# S32K312_M7 register map
Vendor: NXP Semiconductors; File version: 1.3
CPU: CM7 r0p1, little endian, MPU, FPU, VTOR, 4 interrupt priority bits
Registers are 32-bit, read-write, reset 0x0 unless marked. A register's access mark holds for its fields unless they carry their own. Offsets are from the block's base; [hi:lo] are bit positions; lines under a group give offsets from that group; {n}, {i} and the like mark numbered series; 'fields as' and 'values as' point back to an identical list.

## CMU_1 — CMU_FM
Base 0x402BC020
Same registers: CMU_2 0x402BC040
0x00 GCR — Global Configuration Register
  [0] FME — Frequency Meter Enable
    0=bfv_fme_0 (Stops frequency metering); 1=bfv_fme_1 (Starts frequency metering)
0x04 RCCR — Reference Count Configuration Register
  [15:0] REF_CNT — Reference Clock Count
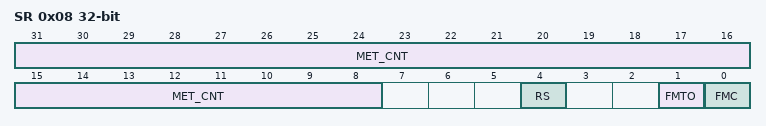
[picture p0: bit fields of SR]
0x08 SR — Status Register
  [31:8] MET_CNT ro — Meter Clock Count
  [4] RS ro — Run Status
    0=bfv_rs_0 (Frequency meter stopped); 1=bfv_rs_1 (Frequency meter running)
  [1] FMTO write-1-clears — Frequency Meter Time Out
  [0] FMC write-1-clears — Frequency Meter Operation Complete
0x0C IER — Interrupt Enable Register
  [0] FMCIE — Frequency Meter Complete Interrupt Enable
    0=bfv_fmcie_0 (Frequency Meter complete interrupt is disabled); 1=bfv_fmcie_1 (Frequency Meter complete interrupt is enabled)

## TSPC
Base 0x402C4000
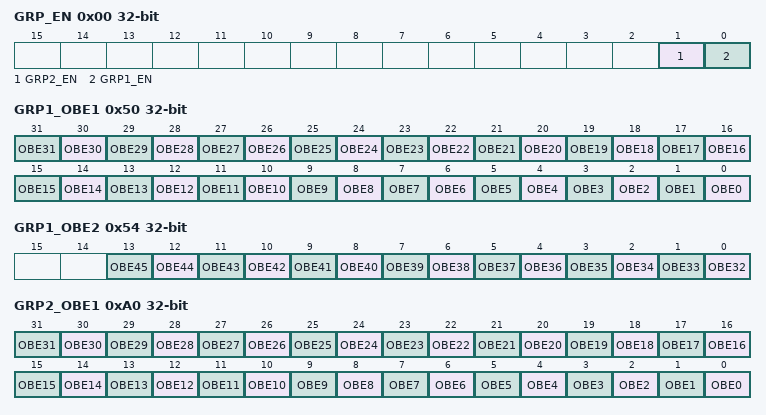
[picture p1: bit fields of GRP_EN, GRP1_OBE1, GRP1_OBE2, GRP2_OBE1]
0x00 GRP_EN — Group Enable
  [1] GRP2_EN — Enable for GRP2_OBEn Register
    0=GRP2_value0 (Disable); 1=GRP2_value1 (Enable)
  [0] GRP1_EN — Enable for GRP1_OBEn Register
    0=GRP1_value0 (Disable); 1=GRP1_value1 (Enable)
0x50 GRP1_OBE1 — Group OBE
  [n] OBE{n} (n=0..31) — Output Buffer Enable
    0=OBE{n}_value0 (OBE pad does not transition if any OBE in group transitions from high to low. The OBE pad value is unaltered at the output.); 1=OBE{n}_value1 (OBE pad transitions from high to low if any OBE in group transitions from high to low.)
0x54 GRP1_OBE2 — Group OBE
  [n-32] OBE{n} (n=32..45) — Output Buffer Enable
    values as GRP1_OBE1.OBE0
0xA0 GRP2_OBE1 — Group OBE
  fields as GRP1_OBE1
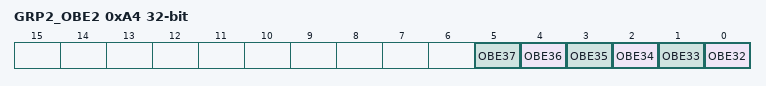
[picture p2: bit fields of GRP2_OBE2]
0xA4 GRP2_OBE2 — Group OBE
  [n-32] OBE{n} (n=32..37) — Output Buffer Enable
    values as GRP1_OBE1.OBE0

## SIRC
Base 0x402C8000
0x04 SR ro reset 0x1 — Status Register
  [0] STATUS — Status bit for SIRC
    0=bfvid_sr_status_0 (SIRC is off or unstable); 1=bfvid_sr_status_1 (SIRC is on and stable)
0x0C MISCELLANEOUS_IN — Miscellaneous input
  [8] STANDBY_ENABLE — Standby Enable for SIRC
    0=SIRC disables in Standby mode; 1=SIRC enables in Standby mode

## SXOSC
Base 0x402CC000
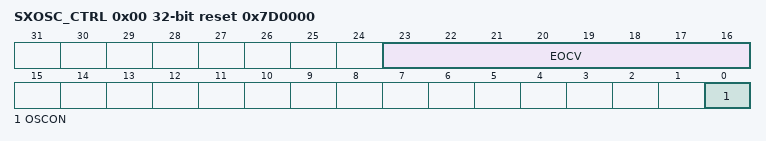
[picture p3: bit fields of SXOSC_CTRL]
0x00 SXOSC_CTRL reset 0x7D0000 — Oscillator Control
  [23:16] EOCV — End Of Count Value
  [0] OSCON — Crystal Oscillator Power-Down Control
    0=Disabled (switched off); 1=Enabled (switched on)
0x04 SXOSC_STAT ro — Oscillator Status
  [31] OSC_STAT — Crystal Oscillator Status
    0=Unstable; 1=Stable

## FIRC
Base 0x402D0000
0x04 Status_Register ro reset 0x1
  [0] STATUS — Status bit for FIRC
    0=FIRC is off or unstable; 1=FIRC is on and stable
0x08 STDBY_ENABLE — Standby Enable Register
  [0] STDBY_EN — Enables or disables FIRC in chip's Standby mode.
    0=Disabled; 1=Enabled

## FXOSC
Base 0x402D4000
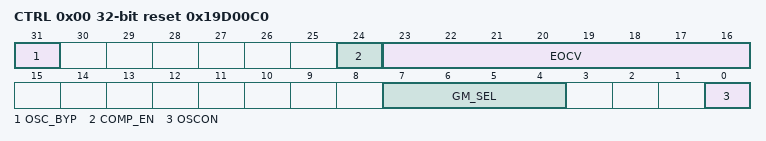
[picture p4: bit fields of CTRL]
0x00 CTRL reset 0x19D00C0 — FXOSC Control Register
  [31] OSC_BYP — Oscillator bypass
    0=Internal oscillator not bypassed; 1=Internal oscillator bypassed
  [24] COMP_EN — Comparator enable
    0=Comparator disabled; 1=Comparator enabled
  [23:16] EOCV — End of count value
  [7:4] GM_SEL — Crystal overdrive protection
    0=0x; 1=0.1004x; 2=0.2009x; 3=0.3013x; 4=0.2343x; 5=0.3348x; 6=0.4345x; 7=0.5349x; 8=0.4679x; 9=0.5684x; 10=0.6681x; 11=0.7678x; 12=0.7016x; 13=0.8013x; 14=0.9003x; 15=1x
  [0] OSCON — Crystal oscillator power-down control
    0=Disables FXOSC; 1=Enables FXOSC
0x04 STAT ro — Oscillator Status Register
  [31] OSC_STAT — Crystal oscillator status
    0=stat_0 (Crystal oscillator is off or on but not stable.); 1=stat_1 (Crystal oscillator is on and providing a stable clock.)

## PLL — PLLDIG
Base 0x402E0000
0x00 PLLCR reset 0x80000000 — PLL Control
  [31] PLLPD — PLL Power Down
    0=bfv_pllcr_pllpd_0 (Powered up); 1=bfv_pllcr_pllpd_1 (Powered down)
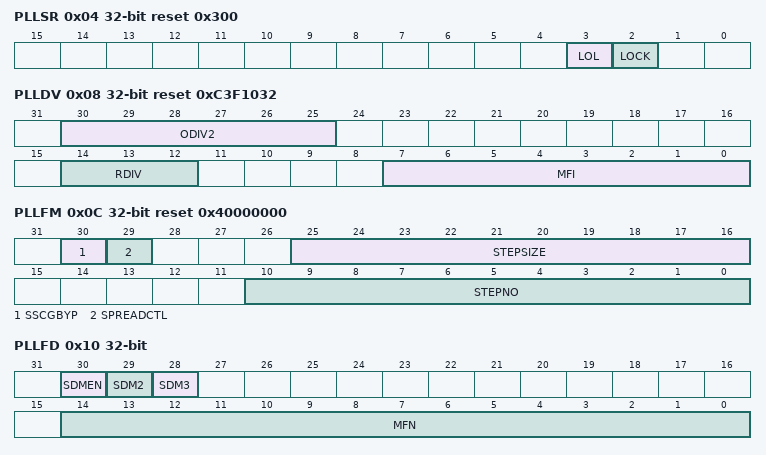
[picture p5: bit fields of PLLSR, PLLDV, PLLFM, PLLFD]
0x04 PLLSR reset 0x300 — PLL Status
  [3] LOL write-1-clears — Loss-Of-Lock Flag
    0=bfv_pllsr_lol_0 (No loss of lock detected); 1=bfv_pllsr_lol_1 (Loss of lock detected)
  [2] LOCK ro — Lock Status
    0=bfv_pllsr_lock_0 (Unlocked); 1=bfv_pllsr_lock_1 (Locked)
0x08 PLLDV reset 0xC3F1032 — PLL Divider
  [30:25] ODIV2 — Output frequency divider for raw PLL clock.
  [14:12] RDIV — Input Clock Predivider
    0=bfv_plldv_rdiv_000 (Divide by 1); 1=bfv_plldv_rdiv_001 (Divide by 1); 2=bfv_plldv_rdiv_010 (Divide by 2); 3=bfv_plldv_rdiv_011 (Divide by 3); 4=bfv_plldv_rdiv_100 (Divide by 4); 5=bfv_plldv_rdiv_101 (Divide by 5); 6=bfv_plldv_rdiv_110 (Divide by 6); 7=bfv_plldv_rdiv_111 (Divide by 7)
  [7:0] MFI — Integer Portion Of Loop Divider
0x0C PLLFM reset 0x40000000 — PLL Frequency Modulation
  [30] SSCGBYP — Frequency Modulation (Spread Spectrum Clock Generation) Bypass
    0=bfv_pllfm_sscgbyp_0 (Not bypassed); 1=bfv_pllfm_sscgbyp_1 (Bypassed)
  [29] SPREADCTL — Modulation Type Selection
    1=bfv_pllfm_spreadctl_1 (Spread below nominal frequency)
  [25:16] STEPSIZE — Frequency Modulation Step Size
  [10:0] STEPNO — Number Of Steps Of Modulation Period Or Frequency Modulation
0x10 PLLFD — PLL Fractional Divider
  [30] SDMEN — Fractional Mode Enable
    0=bfv_pllfd_sdmen_0 (Disabled); 1=bfv_pllfd_sdmen_1 (Enabled)
  [29] SDM2 — Fractional Mode Configuration
  [28] SDM3 — Fractional Mode Configuration
  [14:0] MFN — Numerator Of Fractional Loop Division Factor
0x18 PLLCAL2 reset 0x60000 — PLL Calibration Register 2
  [8:7] ULKCTL — Unlock Control Accuracy
    0=bfv_pllcal2_ulkctl_00 (Unlock range = Expected value +/- 9 (recommended when PLLFM[SSCGBYP] = 1)); 1=bfv_pllcal2_ulkctl_01 (Unlock range = Expected value +/- 17 (recommended when PLLFM[SSCGBYP] = 0)); 2=bfv_pllcal2_ulkctl_10 (Unlock range = Expected value +/- 33); 3=bfv_pllcal2_ulkctl_11 (Unlock range = Expected value +/- 5)
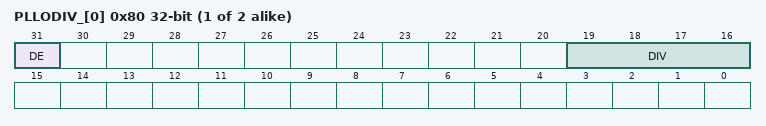
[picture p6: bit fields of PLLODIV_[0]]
{0x80+4i} PLLODIV_[{i}] (i=0..1) — PLL Output Divider
  [31] DE — Divider Enable
    0=bfv_pllodiv_de_0 (Disabled); 1=bfv_pllodiv_de_1 (Enabled)
  [19:16] DIV — Division Value
